# M460_v1 register map
File version: 1.0
Registers are 32-bit, read-write, reset 0x0 unless marked. A register's access mark holds for its fields unless they carry their own. Offsets are from the block's base; [hi:lo] are bit positions; lines under a group give offsets from that group; {n}, {i} and the like mark numbered series; 'fields as' and 'values as' point back to an identical list.

## CLK (part 2 of 2) — CLK Register Map
Base 0x40000200
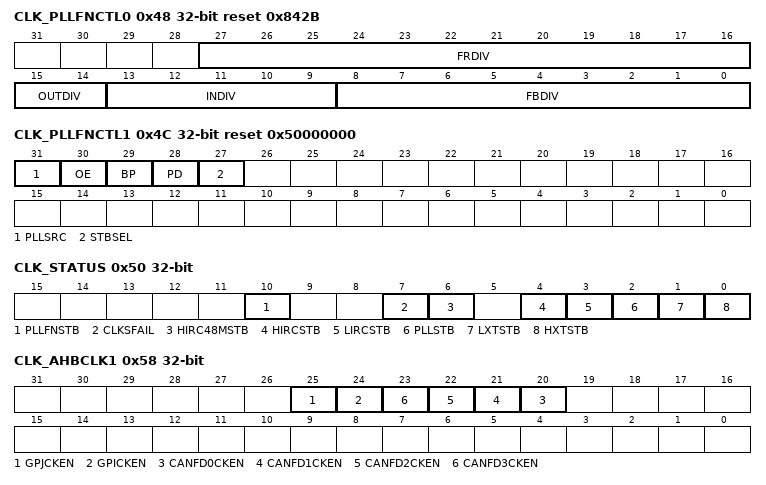
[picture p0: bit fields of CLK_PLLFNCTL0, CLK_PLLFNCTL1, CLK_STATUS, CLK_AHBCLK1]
0x48 CLK_PLLFNCTL0 reset 0x842B — PLLFN Control Register 0
  [27:16] FRDIV — PLL Fractional Divider Control (Write Protect). Refer to the formulas below the table. Note: These bits are write protected. Refer to the SYS_REGLCTL register.
  [15:14] OUTDIV — PLL Output Divider Control (Write Protect). Refer to the formulas below the table. Note: These bits are write protected. Refer to the SYS_REGLCTL register.
  [13:9] INDIV — PLL Input Divider Control (Write Protect). Refer to the formulas below the table. Note: These bits are write protected. Refer to the SYS_REGLCTL register.
  [8:0] FBDIV — PLL Feedback Divider Control (Write Protect). Refer to the formulas below the table. Note: These bits are write protected. Refer to the SYS_REGLCTL register.
0x4C CLK_PLLFNCTL1 reset 0x50000000 — PLLFN Control Register 1
  [31] PLLSRC — PLL Source Clock Selection (Write Protect). Note: This bit is write protected. Refer to the SYS_REGLCTL register.
    0=PLL source clock from 4~32 MHz external high-speed crystal oscillator (HXT); 1=PLL source clock from 12 MHz internal high-speed oscillator (HIRC)
  [30] OE — PLL FOUT Enable Control (Write Protect). Note: This bit is write protected. Refer to the SYS_REGLCTL register.
    0=PLL FOUT Enabled; 1=PLL FOUT is fixed low
  [29] BP — PLL Bypass Control (Write Protect). Note: This bit is write protected. Refer to the SYS_REGLCTL register.
    0=PLL is in normal mode (default); 1=PLL clock output is same as PLL input clock FIN
  [28] PD — Power-down Mode (Write Protect). If set the PDEN bit to 1 in CLK_PWRCTL register, the PLL will enter Power-down mode, too. Note: This bit is write protected. Refer to the SYS_REGLCTL register.
    0=PLL is in normal mode; 1=PLL is in Power-down mode (default)
  [27] STBSEL — PLL Stable Counter Selection (Write Protect). Note: This bit is write protected. Refer to the SYS_REGLCTL register.
    0=PLL stable time is 1200 PLL source clock (suitable for source clock equal to or less than 12 MHz); 1=PLL stable time is 2400 PLL source clock (suitable for source clock larger than 12 MHz)
0x50 CLK_STATUS ro (reset mask 0xFFFFF000) — Clock Status Monitor Register
  [10] PLLFNSTB — Internal PLLFN Clock Source Stable Flag (Read Only)
    0=Internal PLLFN clock is not stable or disabled; 1=Internal PLLFN clock is stable
  [7] CLKSFAIL — Clock Switching Fail Flag (Read Only). This bit is updated when software switches system clock source. If switch target clock is stable, this bit will be set to 0. If switch target clock is not stable, this bit will be set to 1. Note: This bit is read only. After selected clock source is stable, hardware will switch system clock to selected clock automatically, and CLKSFAIL will be cleared automatically by hardware.
    0=Clock switching success; 1=Clock switching failure
  [6] HIRC48MSTB — HIRC48M Clock Source Stable Flag (Read Only)
    0=48 MHz internal high speed RC oscillator (HIRC48M) clock is not stable or disabled; 1=48 MHz internal high speed RC oscillator (HIRC48M) clock is stable and enabled
  [4] HIRCSTB — HIRC Clock Source Stable Flag (Read Only)
    0=12 MHz internal high speed RC oscillator (HIRC) clock is not stable or disabled; 1=12 MHz internal high speed RC oscillator (HIRC) clock is stable and enabled
  [3] LIRCSTB — LIRC Clock Source Stable Flag (Read Only)
    0=10 kHz internal low speed RC oscillator (LIRC) clock is not stable or disabled; 1=10 kHz internal low speed RC oscillator (LIRC) clock is stable and enabled
  [2] PLLSTB — Internal PLL Clock Source Stable Flag (Read Only)
    0=Internal PLL clock is not stable or disabled; 1=Internal PLL clock is stable and enabled
  [1] LXTSTB — LXT Clock Source Stable Flag (Read Only)
    0=32.768 kHz external low speed crystal oscillator (LXT) clock is not stable or disabled; 1=32.768 kHz external low speed crystal oscillator (LXT) clock is stabled and enabled
  [0] HXTSTB — HXT Clock Source Stable Flag (Read Only)
    0=4~24 MHz external high speed crystal oscillator (HXT) clock is not stable or disabled; 1=4~24 MHz external high speed crystal oscillator (HXT) clock is stable and enabled
0x58 CLK_AHBCLK1 — AHB Devices Clock Enable Control Register 1
  [25] GPJCKEN — GPIOJ Clock Enable Bit
    0=GPIOJ clock Disabled; 1=GPIOJ clock Enabled
  [24] GPICKEN — GPIOI Clock Enable Bit
    0=GPIOI clock Disabled; 1=GPIOI clock Enabled
  [n+20] CANFD{n}CKEN (n=0..3) — CANFD{n} Clock Enable Bit
    0=CANFD{n} clock Disabled; 1=CANFD{n} clock Enabled
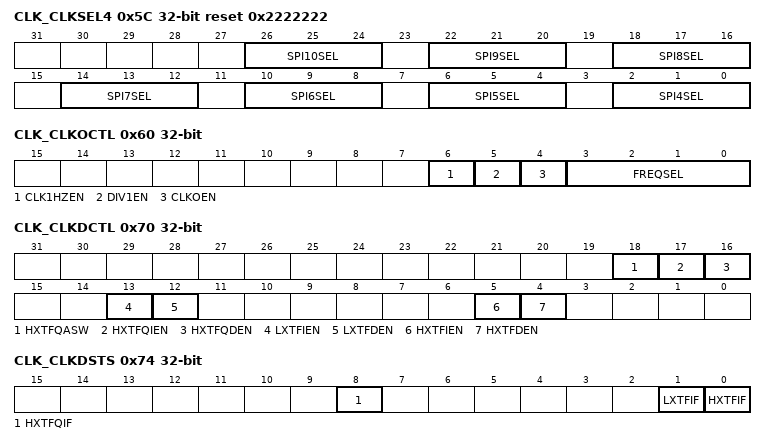
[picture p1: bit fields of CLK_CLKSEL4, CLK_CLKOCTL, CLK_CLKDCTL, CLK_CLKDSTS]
0x5C CLK_CLKSEL4 reset 0x2222222 — Clock Source Select Control Register 4
  [26:24] SPI10SEL — SPI10 Clock Source Selection
    0=Clock source from 4~24 MHz external high speed crystal oscillator (HXT); 1=Clock source from PLL/2; 2=Clock source from PCLK1; 3=Clock source from 12 MHz internal high speed RC oscillator (HIRC)
  [22:20] SPI9SEL — SPI9 Clock Source Selection
    0=Clock source from 4~24 MHz external high speed crystal oscillator (HXT); 1=Clock source from PLL/2; 2=Clock source from PCLK0; 3=Clock source from 12 MHz internal high speed RC oscillator (HIRC)
  [18:16] SPI8SEL — SPI8 Clock Source Selection
    values as SPI10SEL
  [14:12] SPI7SEL — SPI7 Clock Source Selection
    values as SPI9SEL
  [10:8] SPI6SEL — SPI6 Clock Source Selection
    values as SPI10SEL
  [6:4] SPI5SEL — SPI5 Clock Source Selection
    values as SPI9SEL
  [2:0] SPI4SEL — SPI4 Clock Source Selection
    values as SPI10SEL
0x60 CLK_CLKOCTL — Clock Output Control Register
  [6] CLK1HZEN — Clock Output 1Hz Enable Bit
    0=1 Hz clock output for 32.768 kHz frequency compensation Disabled; 1=1 Hz clock output for 32.768 kHz frequency compensation Enabled
  [5] DIV1EN — Clock Output Divide One Enable Bit
    0=Clock Output will output clock with source frequency divided by FREQSEL; 1=Clock Output will output clock with source frequency
  [4] CLKOEN — Clock Output Enable Bit
    0=Clock Output function Disabled; 1=Clock Output function Enabled
  [3:0] FREQSEL — Clock Output Frequency Selection. The formula of output frequency is. Fin is the input clock frequency. Fout is the frequency of divider output clock. N is the 4-bit value of FREQSEL[3:0].
0x70 CLK_CLKDCTL — Clock Fail Detector Control Register
  [18] HXTFQASW — HXT Clock Frequency Range Detector Event Auto Switch Enable Bit. Note: This bit should be set before HXTFQDEN(CLK_CLKDCTL[16]).
    0=4~24 MHz external high speed crystal oscillator (HXT) clock frequency range detector fail event happened and HCLK will not switch to HIRC automatically; 1=4~24 MHz external high speed crystal oscillator (HXT) clock frequency range detector fail event happened and HCLK will switch to HIRC automatically
  [17] HXTFQIEN — HXT Clock Frequency Range Detector Interrupt Enable Bit
    0=4~24 MHz external high speed crystal oscillator (HXT) clock frequency range detector fail interrupt Disabled; 1=4~24 MHz external high speed crystal oscillator (HXT) clock frequency range detector fail interrupt Enabled
  [16] HXTFQDEN — HXT Clock Frequency Range Detector Enable Bit
    0=4~24 MHz external high speed crystal oscillator (HXT) clock frequency range detector Disabled; 1=4~24 MHz external high speed crystal oscillator (HXT) clock frequency range detector Enabled
  [13] LXTFIEN — LXT Clock Fail Interrupt Enable Bit
    0=32.768 kHz external low speed crystal oscillator (LXT) clock fail interrupt Disabled; 1=32.768 kHz external low speed crystal oscillator (LXT) clock fail interrupt Enabled
  [12] LXTFDEN — LXT Clock Fail Detector Enable Bit
    0=32.768 kHz external low speed crystal oscillator (LXT) clock fail detector Disabled; 1=32.768 kHz external low speed crystal oscillator (LXT) clock fail detector Enabled
  [5] HXTFIEN — HXT Clock Fail Interrupt Enable Bit
    0=4~24 MHz external high speed crystal oscillator (HXT) clock fail interrupt Disabled; 1=4~24 MHz external high speed crystal oscillator (HXT) clock fail interrupt Enabled
  [4] HXTFDEN — HXT Clock Fail Detector Enable Bit
    0=4~24 MHz external high speed crystal oscillator (HXT) clock fail detector Disabled; 1=4~24 MHz external high speed crystal oscillator (HXT) clock fail detector Enabled
0x74 CLK_CLKDSTS — Clock Fail Detector Status Register
  [8] HXTFQIF — HXT Clock Frequency Range Detector Interrupt Flag (Write Protect). Note 1: Write 1 to clear the bit to 0. Note 2: This bit is write protected. Refer to the SYS_REGLCTL register.
    0=4~24 MHz external high speed crystal oscillator (HXT) clock frequency is normal; 1=4~24 MHz external high speed crystal oscillator (HXT) clock frequency is abnormal
  [1] LXTFIF — LXT Clock Fail Interrupt Flag (Write Protect). Note 1: Write 1 to clear the bit to 0. Note 2: This bit is write protected. Refer to the SYS_REGLCTL register.
    0=32.768 kHz external low speed crystal oscillator (LXT) clock is normal; 1=32.768 kHz external low speed crystal oscillator (LXT) stops
  [0] HXTFIF — HXT Clock Fail Interrupt Flag (Write Protect). Note 1: Write 1 to clear the bit to 0. Note 2: This bit is write protected. Refer to the SYS_REGLCTL register.
    0=4~24 MHz external high speed crystal oscillator (HXT) clock is normal; 1=4~24 MHz external high speed crystal oscillator (HXT) clock stops
0x78 CLK_CDUPB — Clock Frequency Range Detector Upper Boundary Register
  [9:0] UPERBD — HXT Clock Frequency Range Detector Upper Boundary Value. The bits define the maximum value of frequency range detector window. When HXT frequency higher than this maximum frequency value, the HXT Clock Frequency Range Detector Interrupt Flag will set to 1.
0x7C CLK_CDLOWB — Clock Frequency Range Detector Lower Boundary Register
  [9:0] LOWERBD — HXT Clock Frequency Range Detector Lower Boundary Value. The bits define the minimum value of frequency range detector window. When HXT frequency lower than this minimum frequency value, the HXT Clock Frequency Range Detector Interrupt Flag will set to 1.
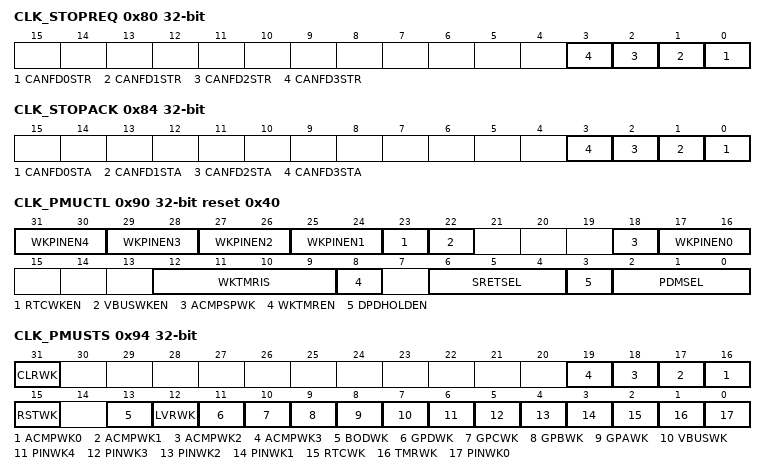
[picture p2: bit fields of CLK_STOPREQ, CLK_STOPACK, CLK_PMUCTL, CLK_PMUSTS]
0x80 CLK_STOPREQ — Clock Stop Request Register
  [n] CANFD{n}STR (n=0..3) — CANFD{n} Clock Stop Request. This bit is used to stop CANFD{n} clock.
    0=CANFD{n} clock is not stopped by this bit. (default); 1=Set this bit and check the CANFD{n}STA(CLK_STOPACK[{n}]) is 1, then CANFD{n} clock stop
0x84 CLK_STOPACK ro — Clock Stop Acknowledge Register
  [n] CANFD{n}STA (n=0..3) — CANFD{n} Clock Stop Acknowledge (Read Only). This bit is used to check CANFD{n} clock stop by setting CANFD{n}STR(CLK_STOPREQ[{n}]).
    0=CANFD{n} clock not stopped; 1=CANFD{n} clock stopped
0x90 CLK_PMUCTL reset 0x40 — Power Manager Control Register
  [31:30] WKPINEN4 — Wake-up Pin4 Enable Bit (Write Protect). This is control register for GPF.6 to wake-up pin. Note 1: These bits are write protected. Refer to the SYS_REGLCTL register. Note 2: Setting IOCTLSEL(RTC_LXTCTL[8]) to avoid GPF.6 unexpected falling edge.
    0=Wake-up pin disabled at Deep Power-down mode; 1=Wake-up pin rising edge enabled at Deep Power-down mode; 2=Wake-up pin falling edge enabled at Deep Power-down mode; 3=Wake-up pin both edge enabled at Deep Power-down mode
  [29:28] WKPINEN3 — Wake-up Pin3 Enable Bit (Write Protect). This is control register for GPB.12 to wake-up pin. Note: These bits are write protected. Refer to the SYS_REGLCTL register.
    values as WKPINEN4
  [27:26] WKPINEN2 — Wake-up Pin2 Enable Bit (Write Protect). This is control register for GPB.2 to wake-up pin. Note: These bits are write protected. Refer to the SYS_REGLCTL register.
    values as WKPINEN4
  [25:24] WKPINEN1 — Wake-up Pin1 Enable Bit (Write Protect). This is control register for GPB.0 to wake-up pin. Note: These bits are write protected. Refer to the SYS_REGLCTL register.
    values as WKPINEN4
  [23] RTCWKEN — RTC Wake-up Enable Bit (Write Protect). Note: This bit is write protected. Refer to the SYS_REGLCTL register.
    0=RTC wake-up disabled at Deep Power-down mode or Standby Power-down mode; 1=RTC wake-up enabled at Deep Power-down mode or Standby Power-down mode
  [22] VBUSWKEN — VBUS Wake-up Enable Bit (Write Protect). Note: This bit is write protected. Refer to the SYS_REGLCTL register.
    0=VBUS transition wake-up disabled at Deep Power-down mode; 1=VBUS transition wake-up enabled at Deep Power-down mode
  [18] ACMPSPWK — ACMP Standby Power-down Mode Wake-up Enable Bit (Write Protect). Note 1: This bit is write protected. Refer to the SYS_REGLCTL register. Note 2: Set FILTSEL(ACMP_CTLx[15:13]) for comparator output filter count selection, the filter clock is LIRC in ACMP SPD mode wakeup function.
    0=ACMP wake-up disabled at Standby Power-down mode; 1=ACMP wake-up enabled at Standby Power-down mode
  [17:16] WKPINEN0 — Wake-up Pin0 Enable Bit (Write Protect). This is control register for GPC.0 to wake-up pin. Note: These bits are write protected. Refer to the SYS_REGLCTL register.
    values as WKPINEN4
  [12:9] WKTMRIS — Wake-up Timer Time-out Interval Select (Write Protect). These bits control wake-up timer time-out interval when chip at DPD/SPD mode. Note: These bits are write protected. Refer to the SYS_REGLCTL register.
    0=Time-out interval is 128 LIRC clocks (12.8ms); 1=Time-out interval is 256 LIRC clocks (25.6ms); 2=Time-out interval is 512 LIRC clocks (51.2ms); 3=Time-out interval is 1024 LIRC clocks (102.4ms); 4=Time-out interval is 4096 LIRC clocks (409.6ms); 5=Time-out interval is 8192 LIRC clocks (819.2ms); 6=Time-out interval is 16384 LIRC clocks (1638.4ms); 7=Time-out interval is 65536 LIRC clocks (6553.6ms); 8=Time-out interval is 131072 LIRC clocks (13107.2ms); 9=Time-out interval is 262144 LIRC clocks (26214.4ms); 10=Time-out interval is 524288 LIRC clocks (52428.8ms); 11=Time-out interval is 1048576 LIRC clocks (104857.6ms)
  [8] WKTMREN — Wake-up Timer Enable Bit (Write Protect). Note: This bit is write protected. Refer to the SYS_REGLCTL register.
    0=Wake-up timer disabled at DPD/SPD mode; 1=Wake-up timer enabled at DPD/SPD mode
  [6:4] SRETSEL — SRAM Retention Range Select Bit (Write Protect). Select SRAM retention range when chip enter SPD mode. Note: These bits are write protected. Refer to the SYS_REGLCTL register.
    0=No SRAM retention; 1=16K SRAM retention when chip enter SPD mode; 2=32K SRAM retention when chip enter SPD mode; 3=64K SRAM retention when chip enter SPD mode; 4=128K SRAM retention when chip enter SPD mode. (default); 5=256K SRAM retention when chip enter SPD mode
  [3] DPDHOLDEN — Deep-Power-Down Mode GPIO Hold Enable Bit (Write Protect). Note: This bit is write protected. Refer to the SYS_REGLCTL register.
    0=When GPIO enters deep power-down mode, all I/O status are tri-state; 1=When GPIO enters deep power-down mode, all I/O status are hold to keep normal operating status. After chip is woken up from deep power-down mode, the I/O are still keep hold status until user set CLK_IOPDCTL[0] to release I/O hold status
  [2:0] PDMSEL — Power-down Mode Selection (Write Protect). These bits control chip power-down mode grade selection when CPU execute WFI/WFE instruction. Note: These bits are write protected. Refer to the SYS_REGLCTL register.
    0=Normal Power-down mode is selected (NPD); 1=Low leakage Power-down mode is selected (LLPD); 2=Fast wake-up Power-down mode is selected (FWPD); 4=Standby Power-down mode is selected (SPD); 6=Deep Power-down mode is selected (DPD)
0x94 CLK_PMUSTS — Power Manager Status Register
  [31] CLRWK — Clear Wake-up Flag. Note: This bit is auto cleared by hardware.
    0=No clear; 1=Clear all wake-up flag
  [n+16] ACMPWK{n} ro (n=0..3) — ACMP{n} Wake-up Flag (Read Only). This flag indicates that wakeup of device from Standby Power-down mode (SPD) was requested with an ACMP{n} transition. Note: This flag needs to be cleared by setting CLRWK(CLK_PMUSTS[31] when entering SPD mode.
  [15] RSTWK ro — RST pin Wake-up Flag (Read Only). This flag indicates that wakeup of device from Deep Power-down mode (DPD) or Standby Power-down (SPD) mode was requested with a RST pin trigger happened. Note: This flag needs to be cleared by setting CLRWK(CLK_PMUSTS[31] when entering SPD/DPD mode.
  [13] BODWK ro — BOD Wake-up Flag (Read Only). This flag indicates that wakeup of device from Standby Power-down mode (SPD) was requested with a BOD happened. Note: This flag needs to be cleared by setting CLRWK(CLK_PMUSTS[31] when entering SPD mode.
  [12] LVRWK ro — LVR Wake-up Flag (Read Only). This flag indicates that wakeup of device from Standby Power-down mode was requested with a LVR happened. Note: This flag needs to be cleared by setting CLRWK(CLK_PMUSTS[31] when entering SPD mode.
  [11] GPDWK ro — GPD Wake-up Flag (Read Only). This flag indicates that wake-up of chip from Standby Power-down mode was requested by a transition of selected one GPD group pins. Note: This flag needs to be cleared by setting CLRWK(CLK_PMUSTS[31] when entering SPD mode.
  [10] GPCWK ro — GPC Wake-up Flag (Read Only). This flag indicates that wake-up of chip from Standby Power-down mode was requested by a transition of selected one GPC group pins. Note: This flag needs to be cleared by setting CLRWK(CLK_PMUSTS[31] when entering SPD mode.
  [9] GPBWK ro — GPB Wake-up Flag (Read Only). This flag indicates that wake-up of chip from Standby Power-down mode was requested by a transition of selected one GPB group pins. Note: This flag needs to be cleared by setting CLRWK(CLK_PMUSTS[31] when entering SPD mode.
  [8] GPAWK ro — GPA Wake-up Flag (Read Only). This flag indicates that wake-up of chip from Standby Power-down mode was requested by a transition of selected one GPA group pins. Note: This flag needs to be cleared by setting CLRWK(CLK_PMUSTS[31] when entering SPD mode.
  [7] VBUSWK ro — VBUS Wake-up Flag (Read Only). This flag indicates that wake-up of chip from Deep Power-down mode was requested by a transition of the WAKEUP pin (PA.12). Note: This flag needs to be cleared by setting CLRWK(CLK_PMUSTS[31] when entering DPD mode.
  [6] PINWK4 ro — Pin4 Wake-up Flag (Read Only). This flag indicates that wake-up of chip from Deep Power-down mode was requested by a transition of the WAKEUP pin (PF.6). Note: This flag needs to be cleared by setting CLRWK(CLK_PMUSTS[31] when entering DPD mode.
  [5] PINWK3 ro — Pin3 Wake-up Flag (Read Only). This flag indicates that wake-up of chip from Deep Power-down mode was requested by a transition of the WAKEUP pin (PB.12). Note: This flag needs to be cleared by setting CLRWK(CLK_PMUSTS[31] when entering DPD mode.
  [4] PINWK2 ro — Pin2 Wake-up Flag (Read Only). This flag indicates that wake-up of chip from Deep Power-down mode was requested by a transition of the WAKEUP pin (PB.2). Note: This flag needs to be cleared by setting CLRWK(CLK_PMUSTS[31] when entering DPD mode.
  [3] PINWK1 ro — Pin1 Wake-up Flag (Read Only). This flag indicates that wake-up of chip from Deep Power-down mode was requested by a transition of the WAKEUP pin (PB.0). Note: This flag needs to be cleared by setting CLRWK(CLK_PMUSTS[31] when entering DPD mode.
  [2] RTCWK ro — RTC Wake-up Flag (Read Only). This flag indicates that wakeup of device from Deep Power-down mode (DPD) or Standby Power-down (SPD) mode was requested with a RTC alarm, tick time or tamper happened. Note: This flag needs to be cleared by setting CLRWK(CLK_PMUSTS[31] when entering SPD/DPD mode.
  [1] TMRWK ro — Timer Wake-up Flag (Read Only). This flag indicates that wake-up of chip from Deep Power-down mode (DPD) or Standby Power-down (SPD) mode was requested by wakeup timer time-out. Note: This flag needs to be cleared by setting CLRWK(CLK_PMUSTS[31] when entering SPD/DPD mode.
  [0] PINWK0 ro — Pin0 Wake-up Flag (Read Only). This flag indicates that wake-up of chip from Deep Power-down mode was requested by a transition of the WAKEUP pin (GPC.0). Note: This flag needs to be cleared by setting CLRWK(CLK_PMUSTS[31] when entering DPD mode.
0x9C CLK_SWKDBCTL — GPIO Standby Power-down Wake-up De-bounce Control Register
  [3:0] SWKDBCLKSEL — Standby Power-down Wake-up De-bounce Sampling Cycle Selection. Note: De-bounce counter clock source is the 10 kHz internal low speed RC oscillator (LIRC).
    0=Sample wake-up input once per 1 clock; 1=Sample wake-up input once per 2 clocks; 2=Sample wake-up input once per 4 clocks; 3=Sample wake-up input once per 8 clocks; 4=Sample wake-up input once per 16 clocks; 5=Sample wake-up input once per 32 clocks; 6=Sample wake-up input once per 64 clocks; 7=Sample wake-up input once per 128 clocks; 8=Sample wake-up input once per 256 clocks; 9=Sample wake-up input once per 2*256 clocks; 10=Sample wake-up input once per 4*256 clocks; 11=Sample wake-up input once per 8*256 clocks; 12=Sample wake-up input once per 16*256 clocks; 13=Sample wake-up input once per 32*256 clocks; 14=Sample wake-up input once per 64*256 clocks; 15=Sample wake-up input once per 128*256 clocks
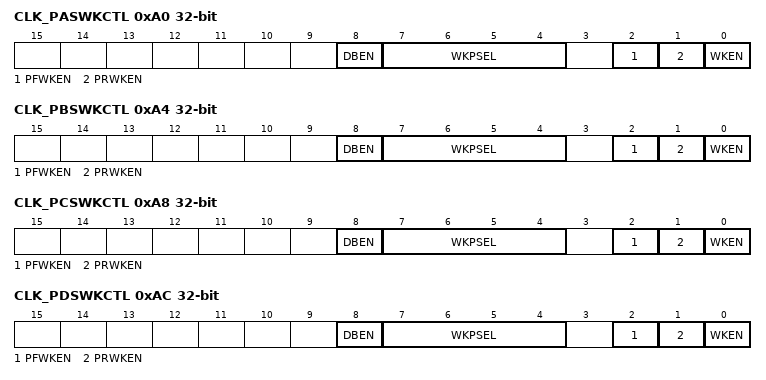
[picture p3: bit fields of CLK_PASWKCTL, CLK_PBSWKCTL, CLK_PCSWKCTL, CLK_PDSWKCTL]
0xA0 CLK_PASWKCTL — GPA Standby Power-down Wake-up Control Register
  [8] DBEN — GPA Input Signal De-bounce Enable Bit. The DBEN bit is used to enable the de-bounce function for each corresponding I/O. If the input signal pulse width cannot be sampled by continuous two de-bounce sample cycle, the input signal transition is seen as the signal bounce and will not trigger the wake-up.The de-bounce clock source is the 10 kHz internal low speed RC oscillator (LIRC). The de-bounce function is valid only for edgetriggered.
    0=Standby power-down wake-up pin De-bounce function Disabled; 1=Standby power-down wake-up pin De-bounce function Enabled
  [7:4] WKPSEL — GPA Standby Power-down Wake-up Pin Select
    0=GPA.0 wake-up function Enabled; 1=GPA.1 wake-up function Enabled; 2=GPA.2 wake-up function Enabled; 3=GPA.3 wake-up function Enabled; 4=GPA.4 wake-up function Enabled; 5=GPA.5 wake-up function Enabled; 6=GPA.6 wake-up function Enabled; 7=GPA.7 wake-up function Enabled; 8=GPA.8 wake-up function Enabled; 9=GPA.9 wake-up function Enabled; 10=GPA.10 wake-up function Enabled; 11=GPA.11 wake-up function Enabled; 12=GPA.12 wake-up function Enabled; 13=GPA.13 wake-up function Enabled; 14=GPA.14 wake-up function Enabled; 15=GPA.15 wake-up function Enabled
  [2] PFWKEN — Pin Falling Edge Wake-up Enable Bit
    0=GPA group pin falling edge wake-up function Disabled; 1=GPA group pin falling edge wake-up function Enabled
  [1] PRWKEN — Pin Rising Edge Wake-up Enable Bit
    0=GPA group pin rising edge wake-up function Disabled; 1=GPA group pin rising edge wake-up function Enabled
  [0] WKEN — Standby Power-down Pin Wake-up Enable Bit
    0=GPA group pin wake-up function Disabled; 1=GPA group pin wake-up function Enabled
0xA4 CLK_PBSWKCTL — GPB Standby Power-down Wake-up Control Register
  [8] DBEN — GPB Input Signal De-bounce Enable Bit. The DBEN bit is used to enable the de-bounce function for each corresponding I/O. If the input signal pulse width cannot be sampled by continuous two de-bounce sample cycle, the input signal transition is seen as the signal bounce and will not trigger the wake-up. The de-bounce clock source is the 10 kHz internal low speed RC oscillator (LIRC). The de-bounce function is valid only for edgetriggered.
    values as CLK_PASWKCTL.DBEN
  [7:4] WKPSEL — GPB Standby Power-down Wake-up Pin Select
    0=GPB.0 wake-up function Enabled; 1=GPB.1 wake-up function Enabled; 2=GPB.2 wake-up function Enabled; 3=GPB.3 wake-up function Enabled; 4=GPB.4 wake-up function Enabled; 5=GPB.5 wake-up function Enabled; 6=GPB.6 wake-up function Enabled; 7=GPB.7 wake-up function Enabled; 8=GPB.8 wake-up function Enabled; 9=GPB.9 wake-up function Enabled; 10=GPB.10 wake-up function Enabled; 11=GPB.11 wake-up function Enabled; 12=GPB.12 wake-up function Enabled; 13=GPB.13 wake-up function Enabled; 14=GPB.14 wake-up function Enabled; 15=GPB.15 wake-up function Enabled
  [2] PFWKEN — Pin Falling Edge Wake-up Enable Bit
    0=GPB group pin falling edge wake-up function Disabled; 1=GPB group pin falling edge wake-up function Enabled
  [1] PRWKEN — Pin Rising Edge Wake-up Enable Bit
    0=GPB group pin rising edge wake-up function Disabled; 1=GPB group pin rising edge wake-up function Enabled
  [0] WKEN — Standby Power-down Pin Wake-up Enable Bit
    0=GPB group pin wake-up function Disabled; 1=GPB group pin wake-up function Enabled
0xA8 CLK_PCSWKCTL — GPC Standby Power-down Wake-up Control Register
  [8] DBEN — GPC Input Signal De-bounce Enable Bit. The DBEN bit is used to enable the de-bounce function for each corresponding I/O. If the input signal pulse width cannot be sampled by continuous two de-bounce sample cycle, the input signal transition is seen as the signal bounce and will not trigger the wake-up.The de-bounce clock source is the 10 kHz internal low speed RC oscillator. Note: The de-bounce function is valid only for edgetriggered.
    values as CLK_PASWKCTL.DBEN
  [7:4] WKPSEL — GPC Standby Power-down Wake-up Pin Select
    0=GPC.0 wake-up function Enabled; 1=GPC.1 wake-up function Enabled; 2=GPC.2 wake-up function Enabled; 3=GPC.3 wake-up function Enabled; 4=GPC.4 wake-up function Enabled; 5=GPC.5 wake-up function Enabled; 6=GPC.6 wake-up function Enabled; 7=GPC.7 wake-up function Enabled; 8=GPC.8 wake-up function Enabled; 9=GPC.9 wake-up function Enabled; 10=GPC.10 wake-up function Enabled; 11=GPC.11 wake-up function Enabled; 12=GPC.12 wake-up function Enabled; 13=GPC.13 wake-up function Enabled; 14=GPC.14 wake-up function Enabled; 15=GPC.15 wake-up function Enabled
  [2] PFWKEN — Pin Falling Edge Wake-up Enable Bit
    0=GPC group pin falling edge wake-up function Disabled; 1=GPC group pin falling edge wake-up function Enabled
  [1] PRWKEN — Pin Rising Edge Wake-up Enable Bit
    0=GPC group pin rising edge wake-up function Disabled; 1=GPC group pin rising edge wake-up function Enabled
  [0] WKEN — Standby Power-down Pin Wake-up Enable Bit
    0=GPC group pin wake-up function Disabled; 1=GPC group pin wake-up function Enabled
0xAC CLK_PDSWKCTL — GPD Standby Power-down Wake-up Control Register
  [8] DBEN — GPD Input Signal De-bounce Enable Bit. The DBEN bit is used to enable the de-bounce function for each corresponding I/O. If the input signal pulse width cannot be sampled by continuous two de-bounce sample cycle, the input signal transition is seen as the signal bounce and will not trigger the wake-up.The de-bounce clock source is the 10 kHz internal low speed RC oscillator. Note: The de-bounce function is valid only for edgetriggered.
    values as CLK_PASWKCTL.DBEN
  [7:4] WKPSEL — GPD Standby Power-down Wake-up Pin Select
    0=GPD.0 wake-up function Enabled; 1=GPD.1 wake-up function Enabled; 2=GPD.2 wake-up function Enabled; 3=GPD.3 wake-up function Enabled; 4=GPD.4 wake-up function Enabled; 5=GPD.5 wake-up function Enabled; 6=GPD.6 wake-up function Enabled; 7=GPD.7 wake-up function Enabled; 8=GPD.8 wake-up function Enabled; 9=GPD.9 wake-up function Enabled; 10=GPD.10 wake-up function Enabled; 11=GPD.11 wake-up function Enabled; 12=GPD.12 wake-up function Enabled; 13=GPD.13 wake-up function Enabled; 14=GPD.14 wake-up function Enabled; 15=GPD.15 wake-up function Enabled
  [2] PFWKEN — Pin Falling Edge Wake-up Enable Bit
    0=GPD group pin falling edge wake-up function Disabled; 1=GPD group pin falling edge wake-up function Enabled
  [1] PRWKEN — Pin Rising Edge Wake-up Enable Bit
    0=GPD group pin rising edge wake-up function Disabled; 1=GPD group pin rising edge wake-up function Enabled
  [0] WKEN — Standby Power-down Pin Wake-up Enable Bit
    0=GPD group pin wake-up function Disabled; 1=GPD group pin wake-up function Enabled
0xB0 CLK_IOPDCTL — GPIO Standby Power-down Control Register
  [0] IOHR — GPIO Hold Release. When GPIO enters deep power-down mode or standby power-down mode, all I/O status are hold to keep normal operating status. After chip is woken up from deep power-down mode or standby power-down mode, the I/O are still keep hold status until user set this bit to release I/O hold status. Note: This bit is auto cleared by hardware.
